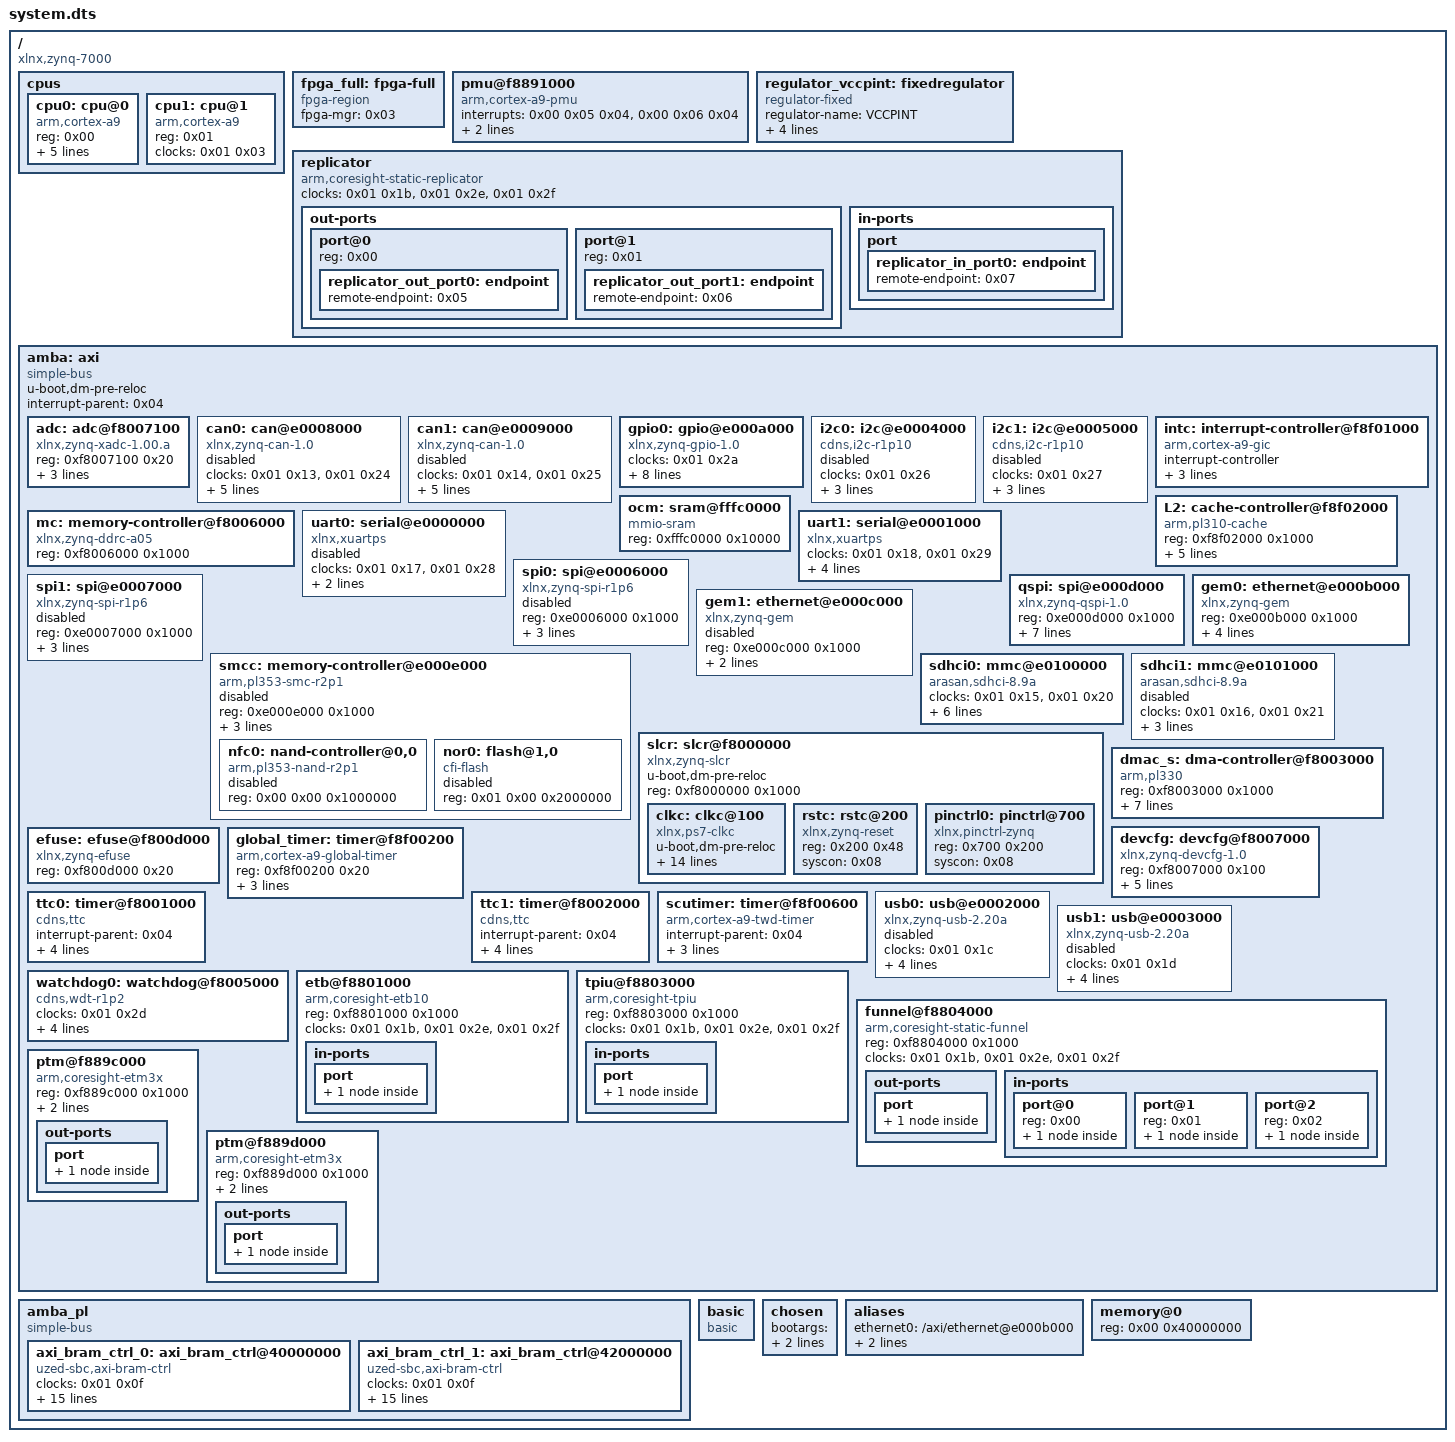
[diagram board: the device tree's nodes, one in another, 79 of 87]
/dts-v1/;

/ {
	#address-cells = <0x01>;
	#size-cells = <0x01>;
	compatible = "xlnx,zynq-7000";

	cpus {
		#address-cells = <0x01>;
		#size-cells = <0x00>;

		cpu0: cpu@0 {
			compatible = "arm,cortex-a9";
			device_type = "cpu";
			reg = <0x00>;
			clocks = <0x01 0x03>;
			clock-latency = <0x3e8>;
			cpu0-supply = <0x02>;
			operating-points = <0xa2c2a 0xf4240 0x51615 0xf4240>;
			phandle = <0x0e>;
		};

		cpu1: cpu@1 {
			compatible = "arm,cortex-a9";
			device_type = "cpu";
			reg = <0x01>;
			clocks = <0x01 0x03>;
			phandle = <0x10>;
		};
	};

	fpga_full: fpga-full {
		compatible = "fpga-region";
		fpga-mgr = <0x03>;
		#address-cells = <0x01>;
		#size-cells = <0x01>;
		ranges;
	};

	pmu@f8891000 {
		compatible = "arm,cortex-a9-pmu";
		interrupts = <0x00 0x05 0x04>, <0x00 0x06 0x04>;
		interrupt-parent = <0x04>;
		reg = <0xf8891000 0x1000 0xf8893000 0x1000>;
	};

	regulator_vccpint: fixedregulator {
		compatible = "regulator-fixed";
		regulator-name = "VCCPINT";
		regulator-min-microvolt = <0xf4240>;
		regulator-max-microvolt = <0xf4240>;
		regulator-boot-on;
		regulator-always-on;
		phandle = <0x02>;
	};

	replicator {
		compatible = "arm,coresight-static-replicator";
		clocks = <0x01 0x1b>, < 0x01 0x2e>, < 0x01 0x2f>;
		clock-names = "apb_pclk", "dbg_trc", "dbg_apb";

		out-ports {
			#address-cells = <0x01>;
			#size-cells = <0x00>;

			port@0 {
				reg = <0x00>;

				replicator_out_port0: endpoint {
					remote-endpoint = <0x05>;
					phandle = <0x0a>;
				};
			};

			port@1 {
				reg = <0x01>;

				replicator_out_port1: endpoint {
					remote-endpoint = <0x06>;
					phandle = <0x09>;
				};
			};
		};

		in-ports {

			port {

				replicator_in_port0: endpoint {
					remote-endpoint = <0x07>;
					phandle = <0x0b>;
				};
			};
		};
	};

	amba: axi {
		u-boot,dm-pre-reloc;
		compatible = "simple-bus";
		#address-cells = <0x01>;
		#size-cells = <0x01>;
		interrupt-parent = <0x04>;
		ranges;

		adc: adc@f8007100 {
			compatible = "xlnx,zynq-xadc-1.00.a";
			reg = <0xf8007100 0x20>;
			interrupts = <0x00 0x07 0x04>;
			interrupt-parent = <0x04>;
			clocks = <0x01 0x0c>;
		};

		can0: can@e0008000 {
			compatible = "xlnx,zynq-can-1.0";
			status = "disabled";
			clocks = <0x01 0x13>, < 0x01 0x24>;
			clock-names = "can_clk", "pclk";
			reg = <0xe0008000 0x1000>;
			interrupts = <0x00 0x1c 0x04>;
			interrupt-parent = <0x04>;
			tx-fifo-depth = <0x40>;
			rx-fifo-depth = <0x40>;
		};

		can1: can@e0009000 {
			compatible = "xlnx,zynq-can-1.0";
			status = "disabled";
			clocks = <0x01 0x14>, < 0x01 0x25>;
			clock-names = "can_clk", "pclk";
			reg = <0xe0009000 0x1000>;
			interrupts = <0x00 0x33 0x04>;
			interrupt-parent = <0x04>;
			tx-fifo-depth = <0x40>;
			rx-fifo-depth = <0x40>;
		};

		gpio0: gpio@e000a000 {
			compatible = "xlnx,zynq-gpio-1.0";
			#gpio-cells = <0x02>;
			clocks = <0x01 0x2a>;
			gpio-controller;
			interrupt-controller;
			#interrupt-cells = <0x02>;
			interrupt-parent = <0x04>;
			interrupts = <0x00 0x14 0x04>;
			reg = <0xe000a000 0x1000>;
			emio-gpio-width = <0x40>;
			gpio-mask-high = <0x00>;
			gpio-mask-low = <0x5600>;
		};

		i2c0: i2c@e0004000 {
			compatible = "cdns,i2c-r1p10";
			status = "disabled";
			clocks = <0x01 0x26>;
			interrupt-parent = <0x04>;
			interrupts = <0x00 0x19 0x04>;
			reg = <0xe0004000 0x1000>;
			#address-cells = <0x01>;
			#size-cells = <0x00>;
		};

		i2c1: i2c@e0005000 {
			compatible = "cdns,i2c-r1p10";
			status = "disabled";
			clocks = <0x01 0x27>;
			interrupt-parent = <0x04>;
			interrupts = <0x00 0x30 0x04>;
			reg = <0xe0005000 0x1000>;
			#address-cells = <0x01>;
			#size-cells = <0x00>;
		};

		intc: interrupt-controller@f8f01000 {
			compatible = "arm,cortex-a9-gic";
			#interrupt-cells = <0x03>;
			interrupt-controller;
			reg = <0xf8f01000 0x1000>, <0xf8f00100 0x100>;
			num_cpus = <0x02>;
			num_interrupts = <0x60>;
			phandle = <0x04>;
		};

		L2: cache-controller@f8f02000 {
			compatible = "arm,pl310-cache";
			reg = <0xf8f02000 0x1000>;
			interrupts = <0x00 0x02 0x04>;
			arm,data-latency = <0x03 0x02 0x02>;
			arm,tag-latency = <0x02 0x02 0x02>;
			cache-unified;
			cache-level = <0x02>;
		};

		mc: memory-controller@f8006000 {
			compatible = "xlnx,zynq-ddrc-a05";
			reg = <0xf8006000 0x1000>;
		};

		ocm: sram@fffc0000 {
			compatible = "mmio-sram";
			reg = <0xfffc0000 0x10000>;
		};

		uart0: serial@e0000000 {
			compatible = "xlnx,xuartps", "cdns,uart-r1p8";
			status = "disabled";
			clocks = <0x01 0x17>, < 0x01 0x28>;
			clock-names = "uart_clk", "pclk";
			reg = <0xe0000000 0x1000>;
			interrupts = <0x00 0x1b 0x04>;
		};

		uart1: serial@e0001000 {
			compatible = "xlnx,xuartps", "cdns,uart-r1p8";
			status = "okay";
			clocks = <0x01 0x18>, < 0x01 0x29>;
			clock-names = "uart_clk", "pclk";
			reg = <0xe0001000 0x1000>;
			interrupts = <0x00 0x32 0x04>;
			cts-override;
			device_type = "serial";
			port-number = <0x00>;
		};

		spi0: spi@e0006000 {
			compatible = "xlnx,zynq-spi-r1p6";
			reg = <0xe0006000 0x1000>;
			status = "disabled";
			interrupt-parent = <0x04>;
			interrupts = <0x00 0x1a 0x04>;
			clocks = <0x01 0x19>, < 0x01 0x22>;
			clock-names = "ref_clk", "pclk";
			#address-cells = <0x01>;
			#size-cells = <0x00>;
		};

		spi1: spi@e0007000 {
			compatible = "xlnx,zynq-spi-r1p6";
			reg = <0xe0007000 0x1000>;
			status = "disabled";
			interrupt-parent = <0x04>;
			interrupts = <0x00 0x31 0x04>;
			clocks = <0x01 0x1a>, < 0x01 0x23>;
			clock-names = "ref_clk", "pclk";
			#address-cells = <0x01>;
			#size-cells = <0x00>;
		};

		qspi: spi@e000d000 {
			compatible = "xlnx,zynq-qspi-1.0";
			reg = <0xe000d000 0x1000>;
			interrupt-parent = <0x04>;
			interrupts = <0x00 0x13 0x04>;
			clocks = <0x01 0x0a>, < 0x01 0x2b>;
			clock-names = "ref_clk", "pclk";
			status = "okay";
			#address-cells = <0x01>;
			#size-cells = <0x00>;
			is-dual = <0x00>;
			num-cs = <0x01>;
			spi-rx-bus-width = <0x04>;
			spi-tx-bus-width = <0x04>;
		};

		gem0: ethernet@e000b000 {
			compatible = "xlnx,zynq-gem", "cdns,gem";
			reg = <0xe000b000 0x1000>;
			status = "okay";
			interrupts = <0x00 0x16 0x04>;
			clocks = <0x01 0x1e>, < 0x01 0x1e>, < 0x01 0x0d>;
			clock-names = "pclk", "hclk", "tx_clk";
			#address-cells = <0x01>;
			#size-cells = <0x00>;
			phy-mode = "rgmii-id";
			xlnx,ptp-enet-clock = <0x69f6bcb>;
		};

		gem1: ethernet@e000c000 {
			compatible = "xlnx,zynq-gem", "cdns,gem";
			reg = <0xe000c000 0x1000>;
			status = "disabled";
			interrupts = <0x00 0x2d 0x04>;
			clocks = <0x01 0x1f>, < 0x01 0x1f>, < 0x01 0x0e>;
			clock-names = "pclk", "hclk", "tx_clk";
			#address-cells = <0x01>;
			#size-cells = <0x00>;
		};

		smcc: memory-controller@e000e000 {
			compatible = "arm,pl353-smc-r2p1", "arm,primecell";
			reg = <0xe000e000 0x1000>;
			status = "disabled";
			clock-names = "memclk", "apb_pclk";
			clocks = <0x01 0x0b>, < 0x01 0x2c>;
			ranges = <0x00 0x00 0xe1000000 0x1000000 0x01 0x00 0xe2000000 0x2000000 0x02 0x00 0xe4000000 0x2000000>;
			#address-cells = <0x02>;
			#size-cells = <0x01>;
			interrupt-parent = <0x04>;
			interrupts = <0x00 0x12 0x04>;

			nfc0: nand-controller@0,0 {
				compatible = "arm,pl353-nand-r2p1";
				reg = <0x00 0x00 0x1000000>;
				status = "disabled";
				#address-cells = <0x01>;
				#size-cells = <0x00>;
			};

			nor0: flash@1,0 {
				status = "disabled";
				compatible = "cfi-flash";
				reg = <0x01 0x00 0x2000000>;
				#address-cells = <0x01>;
				#size-cells = <0x01>;
			};
		};

		sdhci0: mmc@e0100000 {
			compatible = "arasan,sdhci-8.9a";
			status = "okay";
			clock-names = "clk_xin", "clk_ahb";
			clocks = <0x01 0x15>, < 0x01 0x20>;
			interrupt-parent = <0x04>;
			interrupts = <0x00 0x18 0x04>;
			reg = <0xe0100000 0x1000>;
			xlnx,has-cd = <0x01>;
			xlnx,has-power = <0x00>;
			xlnx,has-wp = <0x01>;
		};

		sdhci1: mmc@e0101000 {
			compatible = "arasan,sdhci-8.9a";
			status = "disabled";
			clock-names = "clk_xin", "clk_ahb";
			clocks = <0x01 0x16>, < 0x01 0x21>;
			interrupt-parent = <0x04>;
			interrupts = <0x00 0x2f 0x04>;
			reg = <0xe0101000 0x1000>;
		};

		slcr: slcr@f8000000 {
			u-boot,dm-pre-reloc;
			#address-cells = <0x01>;
			#size-cells = <0x01>;
			compatible = "xlnx,zynq-slcr", "syscon", "simple-mfd";
			reg = <0xf8000000 0x1000>;
			ranges;
			phandle = <0x08>;

			clkc: clkc@100 {
				u-boot,dm-pre-reloc;
				#clock-cells = <0x01>;
				compatible = "xlnx,ps7-clkc";
				fclk-enable = <0x01>;
				clock-output-names = "armpll", "ddrpll", "iopll", "cpu_6or4x", "cpu_3or2x", "cpu_2x", "cpu_1x", "ddr2x", "ddr3x", "dci", "lqspi", "smc", "pcap", "gem0", "gem1", "fclk0", "fclk1", "fclk2", "fclk3", "can0", "can1", "sdio0", "sdio1", "uart0", "uart1", "spi0", "spi1", "dma", "usb0_aper", "usb1_aper", "gem0_aper", "gem1_aper", "sdio0_aper", "sdio1_aper", "spi0_aper", "spi1_aper", "can0_aper", "can1_aper", "i2c0_aper", "i2c1_aper", "uart0_aper", "uart1_aper", "gpio_aper", "lqspi_aper", "smc_aper", "swdt", "dbg_trc", "dbg_apb";
				reg = <0x100 0x100>;
				ps-clk-frequency = <0x1fca055>;
				phandle = <0x01>;
			};

			rstc: rstc@200 {
				compatible = "xlnx,zynq-reset";
				reg = <0x200 0x48>;
				#reset-cells = <0x01>;
				syscon = <0x08>;
			};

			pinctrl0: pinctrl@700 {
				compatible = "xlnx,pinctrl-zynq";
				reg = <0x700 0x200>;
				syscon = <0x08>;
			};
		};

		dmac_s: dma-controller@f8003000 {
			compatible = "arm,pl330", "arm,primecell";
			reg = <0xf8003000 0x1000>;
			interrupt-parent = <0x04>;
			interrupts = <0x00 0x0d 0x04>, <0x00 0x0e 0x04>, <0x00 0x0f 0x04>, <0x00 0x10 0x04>, <0x00 0x11 0x04>, <0x00 0x28 0x04>, <0x00 0x29 0x04>, <0x00 0x2a 0x04>, <0x00 0x2b 0x04>;
			#dma-cells = <0x01>;
			clocks = <0x01 0x1b>;
			clock-names = "apb_pclk";
		};

		devcfg: devcfg@f8007000 {
			compatible = "xlnx,zynq-devcfg-1.0";
			reg = <0xf8007000 0x100>;
			interrupt-parent = <0x04>;
			interrupts = <0x00 0x08 0x04>;
			clocks = <0x01 0x0c>, < 0x01 0x0f>, < 0x01 0x10>, < 0x01 0x11>, < 0x01 0x12>;
			clock-names = "ref_clk", "fclk0", "fclk1", "fclk2", "fclk3";
			syscon = <0x08>;
			phandle = <0x03>;
		};

		efuse: efuse@f800d000 {
			compatible = "xlnx,zynq-efuse";
			reg = <0xf800d000 0x20>;
		};

		global_timer: timer@f8f00200 {
			compatible = "arm,cortex-a9-global-timer";
			reg = <0xf8f00200 0x20>;
			interrupts = <0x01 0x0b 0x301>;
			interrupt-parent = <0x04>;
			clocks = <0x01 0x04>;
		};

		ttc0: timer@f8001000 {
			interrupt-parent = <0x04>;
			interrupts = <0x00 0x0a 0x04>, <0x00 0x0b 0x04>, <0x00 0x0c 0x04>;
			compatible = "cdns,ttc";
			clocks = <0x01 0x06>;
			reg = <0xf8001000 0x1000>;
		};

		ttc1: timer@f8002000 {
			interrupt-parent = <0x04>;
			interrupts = <0x00 0x25 0x04>, <0x00 0x26 0x04>, <0x00 0x27 0x04>;
			compatible = "cdns,ttc";
			clocks = <0x01 0x06>;
			reg = <0xf8002000 0x1000>;
		};

		scutimer: timer@f8f00600 {
			interrupt-parent = <0x04>;
			interrupts = <0x01 0x0d 0x301>;
			compatible = "arm,cortex-a9-twd-timer";
			reg = <0xf8f00600 0x20>;
			clocks = <0x01 0x04>;
		};

		usb0: usb@e0002000 {
			compatible = "xlnx,zynq-usb-2.20a", "chipidea,usb2";
			status = "disabled";
			clocks = <0x01 0x1c>;
			interrupt-parent = <0x04>;
			interrupts = <0x00 0x15 0x04>;
			reg = <0xe0002000 0x1000>;
			phy_type = "ulpi";
		};

		usb1: usb@e0003000 {
			compatible = "xlnx,zynq-usb-2.20a", "chipidea,usb2";
			status = "disabled";
			clocks = <0x01 0x1d>;
			interrupt-parent = <0x04>;
			interrupts = <0x00 0x2c 0x04>;
			reg = <0xe0003000 0x1000>;
			phy_type = "ulpi";
		};

		watchdog0: watchdog@f8005000 {
			clocks = <0x01 0x2d>;
			compatible = "cdns,wdt-r1p2";
			interrupt-parent = <0x04>;
			interrupts = <0x00 0x09 0x01>;
			reg = <0xf8005000 0x1000>;
			timeout-sec = <0x0a>;
		};

		etb@f8801000 {
			compatible = "arm,coresight-etb10", "arm,primecell";
			reg = <0xf8801000 0x1000>;
			clocks = <0x01 0x1b>, < 0x01 0x2e>, < 0x01 0x2f>;
			clock-names = "apb_pclk", "dbg_trc", "dbg_apb";

			in-ports {

				port {

					etb_in_port: endpoint {
						remote-endpoint = <0x09>;
						phandle = <0x06>;
					};
				};
			};
		};

		tpiu@f8803000 {
			compatible = "arm,coresight-tpiu", "arm,primecell";
			reg = <0xf8803000 0x1000>;
			clocks = <0x01 0x1b>, < 0x01 0x2e>, < 0x01 0x2f>;
			clock-names = "apb_pclk", "dbg_trc", "dbg_apb";

			in-ports {

				port {

					tpiu_in_port: endpoint {
						remote-endpoint = <0x0a>;
						phandle = <0x05>;
					};
				};
			};
		};

		funnel@f8804000 {
			compatible = "arm,coresight-static-funnel", "arm,primecell";
			reg = <0xf8804000 0x1000>;
			clocks = <0x01 0x1b>, < 0x01 0x2e>, < 0x01 0x2f>;
			clock-names = "apb_pclk", "dbg_trc", "dbg_apb";

			out-ports {

				port {

					funnel_out_port: endpoint {
						remote-endpoint = <0x0b>;
						phandle = <0x07>;
					};
				};
			};

			in-ports {
				#address-cells = <0x01>;
				#size-cells = <0x00>;

				port@0 {
					reg = <0x00>;

					funnel0_in_port0: endpoint {
						remote-endpoint = <0x0c>;
						phandle = <0x0f>;
					};
				};

				port@1 {
					reg = <0x01>;

					funnel0_in_port1: endpoint {
						remote-endpoint = <0x0d>;
						phandle = <0x11>;
					};
				};

				port@2 {
					reg = <0x02>;

					funnel0_in_port2: endpoint {
					};
				};
			};
		};

		ptm@f889c000 {
			compatible = "arm,coresight-etm3x", "arm,primecell";
			reg = <0xf889c000 0x1000>;
			clocks = <0x01 0x1b>, < 0x01 0x2e>, < 0x01 0x2f>;
			clock-names = "apb_pclk", "dbg_trc", "dbg_apb";
			cpu = <0x0e>;

			out-ports {

				port {

					ptm0_out_port: endpoint {
						remote-endpoint = <0x0f>;
						phandle = <0x0c>;
					};
				};
			};
		};

		ptm@f889d000 {
			compatible = "arm,coresight-etm3x", "arm,primecell";
			reg = <0xf889d000 0x1000>;
			clocks = <0x01 0x1b>, < 0x01 0x2e>, < 0x01 0x2f>;
			clock-names = "apb_pclk", "dbg_trc", "dbg_apb";
			cpu = <0x10>;

			out-ports {

				port {

					ptm1_out_port: endpoint {
						remote-endpoint = <0x11>;
						phandle = <0x0d>;
					};
				};
			};
		};
	};

	amba_pl: amba_pl {
		#address-cells = <0x01>;
		#size-cells = <0x01>;
		compatible = "simple-bus";
		ranges;

		axi_bram_ctrl_0: axi_bram_ctrl@40000000 {
			clock-names = "s_axi_aclk";
			clocks = <0x01 0x0f>;
			compatible = "uzed-sbc,axi-bram-ctrl";
			reg = <0x40000000 0x8000>;
			xlnx,bram-addr-width = <0x0d>;
			xlnx,bram-inst-mode = "EXTERNAL";
			xlnx,ecc = <0x00>;
			xlnx,ecc-onoff-reset-value = <0x00>;
			xlnx,ecc-type = <0x00>;
			xlnx,fault-inject = <0x00>;
			xlnx,memory-depth = <0x2000>;
			xlnx,rd-cmd-optimization = <0x00>;
			xlnx,read-latency = <0x01>;
			xlnx,s-axi-ctrl-addr-width = <0x20>;
			xlnx,s-axi-ctrl-data-width = <0x20>;
			xlnx,s-axi-id-width = <0x0d>;
			xlnx,s-axi-supports-narrow-burst = <0x00>;
			xlnx,single-port-bram = <0x01>;
		};

		axi_bram_ctrl_1: axi_bram_ctrl@42000000 {
			clock-names = "s_axi_aclk";
			clocks = <0x01 0x0f>;
			compatible = "uzed-sbc,axi-bram-ctrl";
			reg = <0x42000000 0x4000>;
			xlnx,bram-addr-width = <0x0c>;
			xlnx,bram-inst-mode = "EXTERNAL";
			xlnx,ecc = <0x00>;
			xlnx,ecc-onoff-reset-value = <0x00>;
			xlnx,ecc-type = <0x00>;
			xlnx,fault-inject = <0x00>;
			xlnx,memory-depth = <0x1000>;
			xlnx,rd-cmd-optimization = <0x00>;
			xlnx,read-latency = <0x01>;
			xlnx,s-axi-ctrl-addr-width = <0x20>;
			xlnx,s-axi-ctrl-data-width = <0x20>;
			xlnx,s-axi-id-width = <0x0d>;
			xlnx,s-axi-supports-narrow-burst = <0x00>;
			xlnx,single-port-bram = <0x01>;
		};
	};

	basic {
		compatible = "basic";
	};

	chosen {
		bootargs = "earlycon console=ttyPS0,115200 clk_ignore_unused root=/dev/mmcblk0p2 rootwait rw earlyprintk";
		stdout-path = "serial0:115200n8";
	};

	aliases {
		ethernet0 = "/axi/ethernet@e000b000";
		serial0 = "/axi/serial@e0001000";
		spi0 = "/axi/spi@e000d000";
	};

	memory@0 {
		device_type = "memory";
		reg = <0x00 0x40000000>;
	};
};
